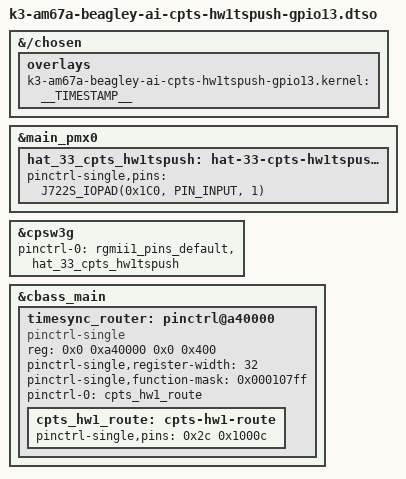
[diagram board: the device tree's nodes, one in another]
// SPDX-License-Identifier: GPL-2.0-only OR MIT
/*
 * DT Overlay for GPIO13 (HAT pin 33) as CPTS hardware timestamp input 1.
 *
 * Pad 0x1C0 (E19, SPI0_D0) in mux mode 1 is CP_GEMAC_CPTS0_HW1TSPUSH. A rising
 * edge on it (for example a GPS 1PPS) latches the CPSW CPTS counter, which
 * Linux reports as external timestamp channel 0 of the CPTS PHC (/dev/ptp0,
 * PTP_EXTTS_REQUEST / extts_enable). The counter is the one that timestamps
 * PTP packets, so this lets a PPS discipline the PHC directly.
 *
 * The HW1TSPUSH pad does not reach the CPTS directly. It is input 12 of the
 * Time Sync Router (TIMESYNC_EVENT_INTROUTER0 at 0xA40000), whose output 10
 * is the CPSW0 cpts_hw1_push. The router comes out of reset with every output
 * disabled and has no mainline driver, so it is modelled here as a
 * pinctrl-single whose "pins" are the per-output mux registers:
 * output N at 0x4 + 4*N, value 0x10000 (enable) | input number.
 * The register block is 1 KiB (TRM memory map, TIMESYNC_EVENT_INTROUTER0_
 * INTR_ROUTER_CFG 0xA40000-0xA40400); a larger reg size makes pinctrl-single
 * read past it and the bus fault oopses the kernel when debugfs is read.
 */

/dts-v1/;
/plugin/;

#include "ti/k3-pinctrl.h"

/*
 * Helper to show loaded overlays under: /proc/device-tree/chosen/overlays/
 */
&{/chosen} {
	overlays {
		k3-am67a-beagley-ai-cpts-hw1tspush-gpio13.kernel = __TIMESTAMP__;
	};
};

&main_pmx0 {
	hat_33_cpts_hw1tspush: hat-33-cpts-hw1tspush-pins {
		pinctrl-single,pins = <
			J722S_IOPAD(0x1C0, PIN_INPUT, 1) /* (E19) SPI0_D0.CP_GEMAC_CPTS0_HW1TSPUSH */
		>;
	};
};

&cpsw3g {
	pinctrl-names = "default";
	pinctrl-0 = <&rgmii1_pins_default>, <&hat_33_cpts_hw1tspush>;
};

&cbass_main {
	#address-cells = <2>;
	#size-cells = <2>;

	timesync_router: pinctrl@a40000 {
		compatible = "pinctrl-single";
		reg = <0x0 0xa40000 0x0 0x400>;
		#pinctrl-cells = <1>;
		pinctrl-single,register-width = <32>;
		pinctrl-single,function-mask = <0x000107ff>;
		pinctrl-names = "default";
		pinctrl-0 = <&cpts_hw1_route>;

		/* in12 [CP_GEMAC_CPTS0_HW1TSPUSH pin] -> out10 [cpsw cpts hw1_push] */
		cpts_hw1_route: cpts-hw1-route {
			pinctrl-single,pins = <0x2c 0x1000c>;
		};
	};
};
